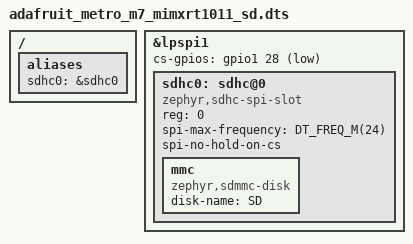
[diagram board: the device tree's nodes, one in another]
/*
 * Copyright (c) 2025, George White
 *
 * SPDX-License-Identifier: Apache-2.0
 */

/dts-v1/;

#include "adafruit_metro_m7.dts"

/ {
	aliases {
		sdhc0 = &sdhc0;
	};
};

&lpspi1 {
	cs-gpios = <&gpio1 28 GPIO_ACTIVE_LOW>;

	sdhc0: sdhc@0 {
		compatible = "zephyr,sdhc-spi-slot";
		reg = <0>;
		status = "okay";
		spi-max-frequency = <DT_FREQ_M(24)>;
		spi-no-hold-on-cs;
		mmc {
			compatible = "zephyr,sdmmc-disk";
			disk-name = "SD";
			status = "okay";
		};
	};
};
